# DA14580 register map
Vendor: Dialog; Series: DA14580x; File version: 1.2
CPU: CM0 r1p0, little endian, MPU, FPU, 3 interrupt priority bits
Registers are 16-bit, read-write, reset 0x0 unless marked. A register's access mark holds for its fields unless they carry their own. Offsets are from the block's base; [hi:lo] are bit positions.

## NVIC — Cortex M0 NVIC registers
Base 0xE000E100
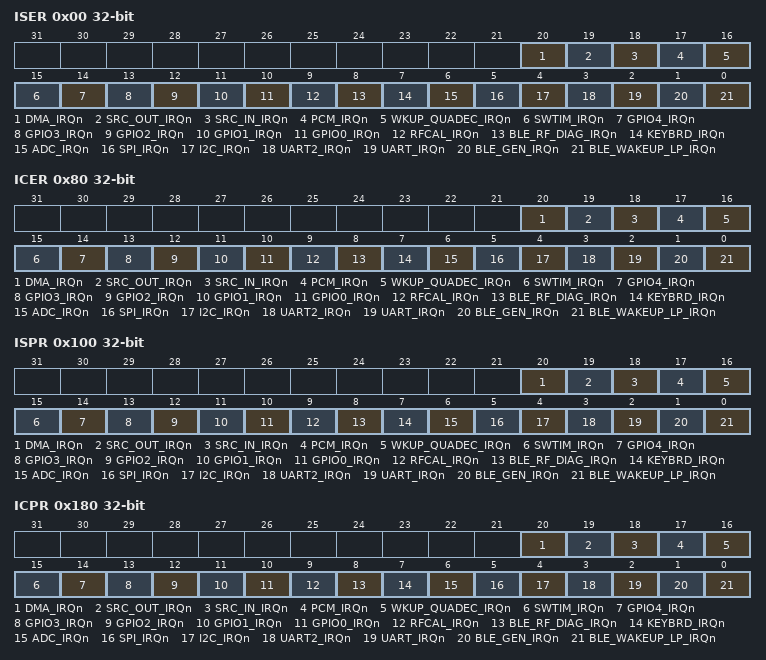
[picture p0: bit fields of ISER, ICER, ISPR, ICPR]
0x00 ISER 32-bit — Interrupt set-enable register
  [20] DMA_IRQn — DMA Interrupt (set-enable bit)
  [19] SRC_OUT_IRQn — Sample rate converter output Interrupt (set-enable bit)
  [18] SRC_IN_IRQn — Sample rate converter input Interrupt (set-enable bit)
  [17] PCM_IRQn — PCM Interrupt (set-enable bit)
  [16] WKUP_QUADEC_IRQn — Combined Wake up Capture Timer, GPIO and QuadDecoder interrupt (set-enable bit)
  [15] SWTIM_IRQn — Software timer Interrupt (set-enable bit)
  [14] GPIO4_IRQn — GPIO4 interrupt through debounce (Interrupt set-enable bit)
  [13] GPIO3_IRQn — IGPIO3 interrupt through debounce (Interrupt set-enable bit)
  [12] GPIO2_IRQn — GPIO2 interrupt through debounce (Interrupt set-enable bit)
  [11] GPIO1_IRQn — GPIO1 interrupt through debounce (Interrupt set-enable bit)
  [10] GPIO0_IRQn — GPIO0 interrupt through debounce (Interrupt set-enable bit)
  [9] RFCAL_IRQn — RFCAL_IRQn (Interrupt set-enable bit)
  [8] BLE_RF_DIAG_IRQn — BLE baseband or Radio diagnostic (Interrupt set-enable bit))
  [7] KEYBRD_IRQn — KEYBRD_IRQn (Interrupt set-enable bit)
  [6] ADC_IRQn — ADC_IRQn (Interrupt set-enable bit)
  [5] SPI_IRQn — SPI_IRQn (Interrupt set-enable bit)
  [4] I2C_IRQn — I2C_IRQn (Interrupt set-enable bit)
  [3] UART2_IRQn — UART2_IRQn (Interrupt set-enable bit)
  [2] UART_IRQn — UART_IRQn (Interrupt set-enable bit)
  [1] BLE_GEN_IRQn — BLE_GEN_IRQn (Interrupt set-enable bit)
  [0] BLE_WAKEUP_LP_IRQn — BLE_WAKEUP_LP_IRQn (Interrupt set-enable bit)
0x80 ICER 32-bit — Interrupt clear-enable register
  [20] DMA_IRQn — DMA Interrupt (clear-enable bit)
  [19] SRC_OUT_IRQn — Sample rate converter output Interrupt (clear-enable bit)
  [18] SRC_IN_IRQn — Sample rate converter input Interrupt (clear-enable bit)
  [17] PCM_IRQn — PCM Interrupt (clear-enable bit)
  [16] WKUP_QUADEC_IRQn — Combined Wake up Capture Timer, GPIO and QuadDecoder interrupt (clear-enable bit)
  [15] SWTIM_IRQn — Software timer Interrupt (clear-enable bit)
  [14] GPIO4_IRQn — GPIO4 interrupt through debounce (Interrupt clear-enable bit)
  [13] GPIO3_IRQn — IGPIO3 interrupt through debounce (Interrupt clear-enable bit)
  [12] GPIO2_IRQn — GPIO2 interrupt through debounce (Interrupt clear-enable bit)
  [11] GPIO1_IRQn — GPIO1 interrupt through debounce (Interrupt clear-enable bit)
  [10] GPIO0_IRQn — GPIO0 interrupt through debounce (Interrupt clear-enable bit)
  [9] RFCAL_IRQn — RFCAL_IRQn (Interrupt clear-enable bit)
  [8] BLE_RF_DIAG_IRQn — BLE baseband or Radio diagnostic (Interrupt clear-enable bit))
  [7] KEYBRD_IRQn — KEYBRD_IRQn (Interrupt clear-enable bit)
  [6] ADC_IRQn — ADC_IRQn (Interrupt clear-enable bit)
  [5] SPI_IRQn — SPI_IRQn (Interrupt clear-enable bit)
  [4] I2C_IRQn — I2C_IRQn (Interrupt clear-enable bit)
  [3] UART2_IRQn — UART2_IRQn (Interrupt clear-enable bit)
  [2] UART_IRQn — UART_IRQn (Interrupt clear-enable bit)
  [1] BLE_GEN_IRQn — BLE_GEN_IRQn (Interrupt clear-enable bit)
  [0] BLE_WAKEUP_LP_IRQn — BLE_WAKEUP_LP_IRQn (Interrupt clear-enable bit)
0x100 ISPR 32-bit — Interrupt set-pending register
  [20] DMA_IRQn — DMA Interrupt (set-pending bit)
  [19] SRC_OUT_IRQn — Sample rate converter output Interrupt (set-pending bit)
  [18] SRC_IN_IRQn — Sample rate converter input Interrupt (set-pending bit)
  [17] PCM_IRQn — PCM Interrupt (set-pending bit)
  [16] WKUP_QUADEC_IRQn — Combined Wake up Capture Timer, GPIO and QuadDecoder interrupt (set-pending bit)
  [15] SWTIM_IRQn — Software timer Interrupt (set-pending bit)
  [14] GPIO4_IRQn — GPIO4 interrupt through debounce (Interrupt set-pending bit)
  [13] GPIO3_IRQn — IGPIO3 interrupt through debounce (Interrupt set-pending bit)
  [12] GPIO2_IRQn — GPIO2 interrupt through debounce (Interrupt set-pending bit)
  [11] GPIO1_IRQn — GPIO1 interrupt through debounce (Interrupt set-pending bit)
  [10] GPIO0_IRQn — GPIO0 interrupt through debounce (Interrupt set-pending bit)
  [9] RFCAL_IRQn — RFCAL_IRQn (Interrupt set-pending bit)
  [8] BLE_RF_DIAG_IRQn — BLE baseband or Radio diagnostic (Interrupt set-pending bit))
  [7] KEYBRD_IRQn — KEYBRD_IRQn (Interrupt set-pending bit)
  [6] ADC_IRQn — ADC_IRQn (Interrupt set-pending bit)
  [5] SPI_IRQn — SPI_IRQn (Interrupt set-pending bit)
  [4] I2C_IRQn — I2C_IRQn (Interrupt set-pending bit)
  [3] UART2_IRQn — UART2_IRQn (Interrupt set-pending bit)
  [2] UART_IRQn — UART_IRQn (Interrupt set-pending bit)
  [1] BLE_GEN_IRQn — BLE_GEN_IRQn (Interrupt set-pending bit)
  [0] BLE_WAKEUP_LP_IRQn — BLE_WAKEUP_LP_IRQn (Interrupt set-pending bit)
0x180 ICPR 32-bit — Interrupt clear-pending register
  [20] DMA_IRQn — DMA Interrupt (clear-pending bit)
  [19] SRC_OUT_IRQn — Sample rate converter output Interrupt (clear-pending bit)
  [18] SRC_IN_IRQn — Sample rate converter input Interrupt (clear-pending bit)
  [17] PCM_IRQn — PCM Interrupt (clear-pending bit)
  [16] WKUP_QUADEC_IRQn — Combined Wake up Capture Timer, GPIO and QuadDecoder interrupt (clear-pending bit)
  [15] SWTIM_IRQn — Software timer Interrupt (clear-pending bit)
  [14] GPIO4_IRQn — GPIO4 interrupt through debounce (Interrupt clear-pending bit)
  [13] GPIO3_IRQn — IGPIO3 interrupt through debounce (Interrupt clear-pending bit)
  [12] GPIO2_IRQn — GPIO2 interrupt through debounce (Interrupt clear-pending bit)
  [11] GPIO1_IRQn — GPIO1 interrupt through debounce (Interrupt clear-pending bit)
  [10] GPIO0_IRQn — GPIO0 interrupt through debounce (Interrupt clear-pending bit)
  [9] RFCAL_IRQn — RFCAL_IRQn (Interrupt clear-pending bit)
  [8] BLE_RF_DIAG_IRQn — BLE baseband or Radio diagnostic (Interrupt clear-pending bit))
  [7] KEYBRD_IRQn — KEYBRD_IRQn (Interrupt clear-pending bit)
  [6] ADC_IRQn — ADC_IRQn (Interrupt clear-pending bit)
  [5] SPI_IRQn — SPI_IRQn (Interrupt clear-pending bit)
  [4] I2C_IRQn — I2C_IRQn (Interrupt clear-pending bit)
  [3] UART2_IRQn — UART2_IRQn (Interrupt clear-pending bit)
  [2] UART_IRQn — UART_IRQn (Interrupt clear-pending bit)
  [1] BLE_GEN_IRQn — BLE_GEN_IRQn (Interrupt clear-pending bit)
  [0] BLE_WAKEUP_LP_IRQn — BLE_WAKEUP_LP_IRQn (Interrupt clear-pending bit)
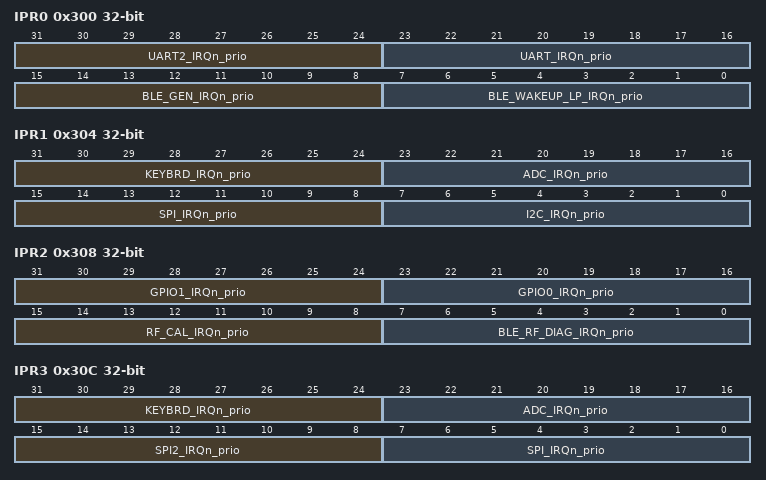
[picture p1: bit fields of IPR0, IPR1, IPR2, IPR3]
0x300 IPR0 32-bit — Interrupt priority register 0
  [31:24] UART2_IRQn_prio — UART2_IRQn[7:0] bits (Interrupt priority)
  [23:16] UART_IRQn_prio — UART_IRQn[7:0] bits (Interrupt priority)
  [15:8] BLE_GEN_IRQn_prio — BLE_GEN_IRQn[7:0] bits (Interrupt priority)
  [7:0] BLE_WAKEUP_LP_IRQn_prio — BLE_WAKEUP_LP_IRQn[7:0] bits (Interrupt priority)
0x304 IPR1 32-bit — Interrupt priority register 1
  [31:24] KEYBRD_IRQn_prio — KEYBRD_IRQn[7:0] bits (Interrupt priority)
  [23:16] ADC_IRQn_prio — ADC_IRQn[7:0] bits (Interrupt priority)
  [15:8] SPI_IRQn_prio — SPI_IRQn[7:0] bits (Interrupt priority)
  [7:0] I2C_IRQn_prio — I2C_IRQn[7:0] bits (Interrupt priority)
0x308 IPR2 32-bit — Interrupt priority register 2
  [31:24] GPIO1_IRQn_prio — GPIO1_IRQn[7:0] bits (Interrupt priority)
  [23:16] GPIO0_IRQn_prio — GPIO0_IRQn[7:0] bits (Interrupt priority)
  [15:8] RF_CAL_IRQn_prio — RF_CAL_IRQn[7:0] bits (Interrupt priority)
  [7:0] BLE_RF_DIAG_IRQn_prio — BLE_RF_DIAG_IRQn[7:0] bits (Interrupt priority)
0x30C IPR3 32-bit — Interrupt priority register 3
  [31:24] KEYBRD_IRQn_prio — KEYBRD_IRQn[7:0] bits (Interrupt priority)
  [23:16] ADC_IRQn_prio — ADC_IRQn[7:0] bits (Interrupt priority)
  [15:8] SPI2_IRQn_prio — SPI2_IRQn[7:0] bits (Interrupt priority)
  [7:0] SPI_IRQn_prio — SPI_IRQn[7:0] bits (Interrupt priority)
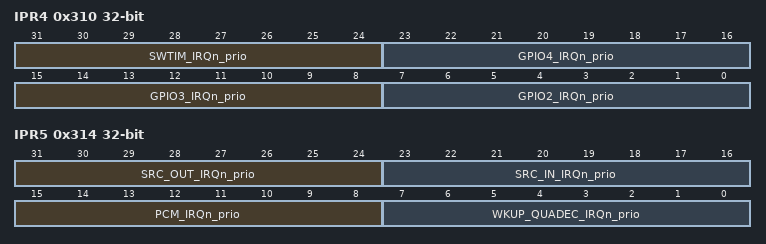
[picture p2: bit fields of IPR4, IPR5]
0x310 IPR4 32-bit — Interrupt priority register 4
  [31:24] SWTIM_IRQn_prio — SWTIM_IRQn[7:0] bits (Interrupt priority)
  [23:16] GPIO4_IRQn_prio — GPIO4_IRQn[7:0] bits (Interrupt priority)
  [15:8] GPIO3_IRQn_prio — GPIO3_IRQn[7:0] bits (Interrupt priority)
  [7:0] GPIO2_IRQn_prio — GPIO2_IRQn[7:0] bits (Interrupt priority)
0x314 IPR5 32-bit — Interrupt priority register 5
  [31:24] SRC_OUT_IRQn_prio — SRC_OUT_IRQn[7:0] bits (Interrupt priority)
  [23:16] SRC_IN_IRQn_prio — SRC_IN_IRQn[7:0] bits (Interrupt priority)
  [15:8] PCM_IRQn_prio — PCM_IRQn[7:0] bits (Interrupt priority)
  [7:0] WKUP_QUADEC_IRQn_prio — WKUP_QUADEC_IRQn[7:0] bits (Interrupt priority)
0x318 IPR6 32-bit — Interrupt priority register 6
  [7:0] DMA_IRQn_prio — DMA_IRQn[7:0] bits (Interrupt priority)

## Notices in the file
Copyright (C) 2018 Dialog Semiconductor.
This computer program includes Confidential, Proprietary Information
of Dialog Semiconductor. All Rights Reserved.
